# iom480ae register map
Registers are 32-bit, access not given, no defined reset value unless marked. A register's access mark holds for its fields unless they carry their own. Addresses are absolute; registers are grouped by the start of their names; [hi:lo] are bit positions; 'fields as' and 'values as' point back to an identical list.

## HSUSBD
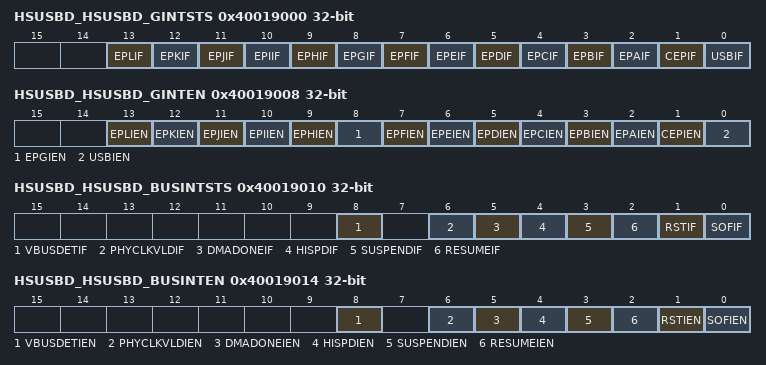
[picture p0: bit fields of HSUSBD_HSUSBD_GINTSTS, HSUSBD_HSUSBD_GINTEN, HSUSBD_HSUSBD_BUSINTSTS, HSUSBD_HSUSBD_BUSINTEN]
0x40019000 HSUSBD_HSUSBD_GINTSTS
  [13] EPLIF, [12] EPKIF, [11] EPJIF, [10] EPIIF, [9] EPHIF, [8] EPGIF, [7] EPFIF, [6] EPEIF, [5] EPDIF, [4] EPCIF, [3] EPBIF, [2] EPAIF, [1] CEPIF, [0] USBIF
0x40019008 HSUSBD_HSUSBD_GINTEN
  [13] EPLIEN, [12] EPKIEN, [11] EPJIEN, [10] EPIIEN, [9] EPHIEN, [8] EPGIEN, [7] EPFIEN, [6] EPEIEN, [5] EPDIEN, [4] EPCIEN, [3] EPBIEN, [2] EPAIEN, [1] CEPIEN, [0] USBIEN
0x40019010 HSUSBD_HSUSBD_BUSINTSTS
  [8] VBUSDETIF, [6] PHYCLKVLDIF, [5] DMADONEIF, [4] HISPDIF, [3] SUSPENDIF, [2] RESUMEIF, [1] RSTIF, [0] SOFIF
0x40019014 HSUSBD_HSUSBD_BUSINTEN
  [8] VBUSDETIEN, [6] PHYCLKVLDIEN, [5] DMADONEIEN, [4] HISPDIEN, [3] SUSPENDIEN, [2] RESUMEIEN, [1] RSTIEN, [0] SOFIEN
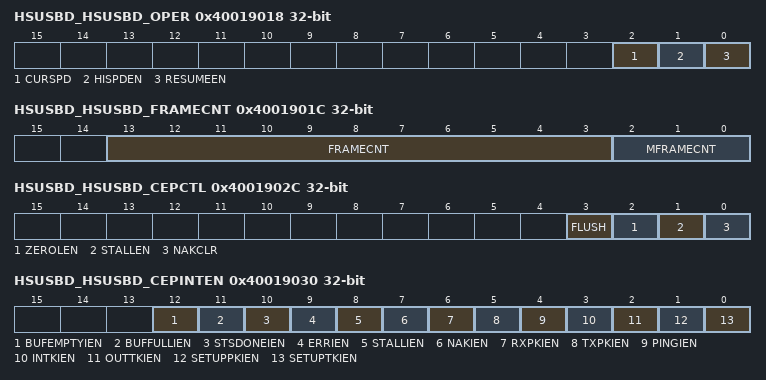
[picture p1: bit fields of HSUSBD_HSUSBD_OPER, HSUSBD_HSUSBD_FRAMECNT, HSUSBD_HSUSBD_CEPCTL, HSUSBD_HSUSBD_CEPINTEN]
0x40019018 HSUSBD_HSUSBD_OPER
  [2] CURSPD, [1] HISPDEN, [0] RESUMEEN
0x4001901C HSUSBD_HSUSBD_FRAMECNT
  [13:3] FRAMECNT, [2:0] MFRAMECNT
0x40019020 HSUSBD_HSUSBD_FADDR
  [6:0] FADDR
0x40019024 HSUSBD_HSUSBD_TEST
  [2:0] TESTMODE
0x40019028 HSUSBD_HSUSBD_CEPDAT
0x4001902C HSUSBD_HSUSBD_CEPCTL
  [3] FLUSH, [2] ZEROLEN, [1] STALLEN, [0] NAKCLR
0x40019030 HSUSBD_HSUSBD_CEPINTEN
  [12] BUFEMPTYIEN, [11] BUFFULLIEN, [10] STSDONEIEN, [9] ERRIEN, [8] STALLIEN, [7] NAKIEN, [6] RXPKIEN, [5] TXPKIEN, [4] PINGIEN, [3] INTKIEN, [2] OUTTKIEN, [1] SETUPPKIEN, [0] SETUPTKIEN
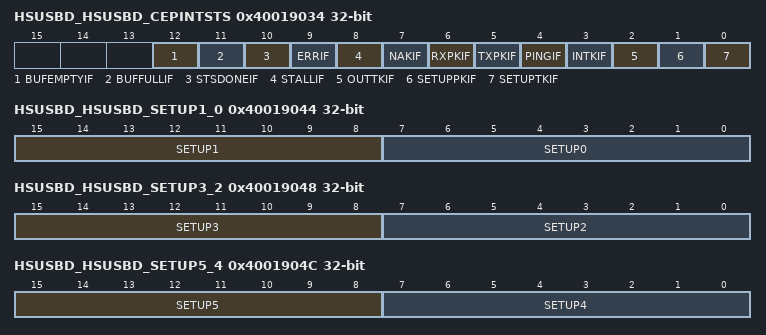
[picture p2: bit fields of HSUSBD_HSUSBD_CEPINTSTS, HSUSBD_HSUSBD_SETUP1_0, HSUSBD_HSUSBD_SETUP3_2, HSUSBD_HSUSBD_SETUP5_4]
0x40019034 HSUSBD_HSUSBD_CEPINTSTS
  [12] BUFEMPTYIF, [11] BUFFULLIF, [10] STSDONEIF, [9] ERRIF, [8] STALLIF, [7] NAKIF, [6] RXPKIF, [5] TXPKIF, [4] PINGIF, [3] INTKIF, [2] OUTTKIF, [1] SETUPPKIF, [0] SETUPTKIF
0x40019038 HSUSBD_HSUSBD_CEPTXCNT
  [7:0] TXCNT
0x4001903C HSUSBD_HSUSBD_CEPRXCNT
  [7:0] RXCNT
0x40019040 HSUSBD_HSUSBD_CEPDATCNT
  [15:0] DATCNT
0x40019044 HSUSBD_HSUSBD_SETUP1_0
  [15:8] SETUP1, [7:0] SETUP0
0x40019048 HSUSBD_HSUSBD_SETUP3_2
  [15:8] SETUP3, [7:0] SETUP2
0x4001904C HSUSBD_HSUSBD_SETUP5_4
  [15:8] SETUP5, [7:0] SETUP4
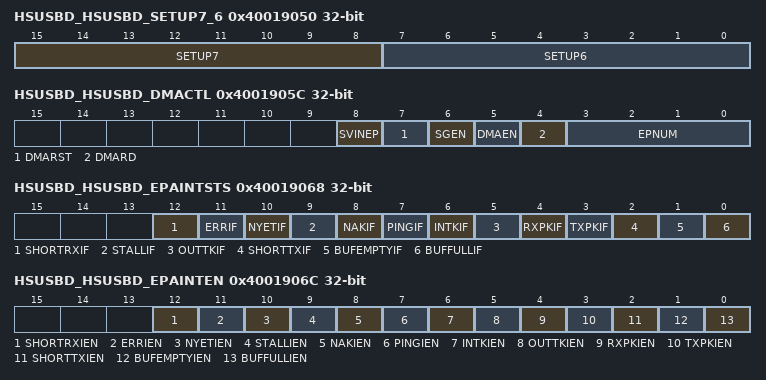
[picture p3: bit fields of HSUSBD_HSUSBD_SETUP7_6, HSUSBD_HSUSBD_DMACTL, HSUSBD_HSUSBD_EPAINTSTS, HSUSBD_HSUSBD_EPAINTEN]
0x40019050 HSUSBD_HSUSBD_SETUP7_6
  [15:8] SETUP7, [7:0] SETUP6
0x40019054 HSUSBD_HSUSBD_CEPBUFSTART
  [11:0] SADDR
0x40019058 HSUSBD_HSUSBD_CEPBUFEND
  [11:0] EADDR
0x4001905C HSUSBD_HSUSBD_DMACTL
  [8] SVINEP, [7] DMARST, [6] SGEN, [5] DMAEN, [4] DMARD, [3:0] EPNUM
0x40019060 HSUSBD_HSUSBD_DMACNT
  [19:0] DMACNT
0x40019064 HSUSBD_HSUSBD_EPADAT
0x40019068 HSUSBD_HSUSBD_EPAINTSTS
  [12] SHORTRXIF, [11] ERRIF, [10] NYETIF, [9] STALLIF, [8] NAKIF, [7] PINGIF, [6] INTKIF, [5] OUTTKIF, [4] RXPKIF, [3] TXPKIF, [2] SHORTTXIF, [1] BUFEMPTYIF, [0] BUFFULLIF
0x4001906C HSUSBD_HSUSBD_EPAINTEN
  [12] SHORTRXIEN, [11] ERRIEN, [10] NYETIEN, [9] STALLIEN, [8] NAKIEN, [7] PINGIEN, [6] INTKIEN, [5] OUTTKIEN, [4] RXPKIEN, [3] TXPKIEN, [2] SHORTTXIEN, [1] BUFEMPTYIEN, [0] BUFFULLIEN
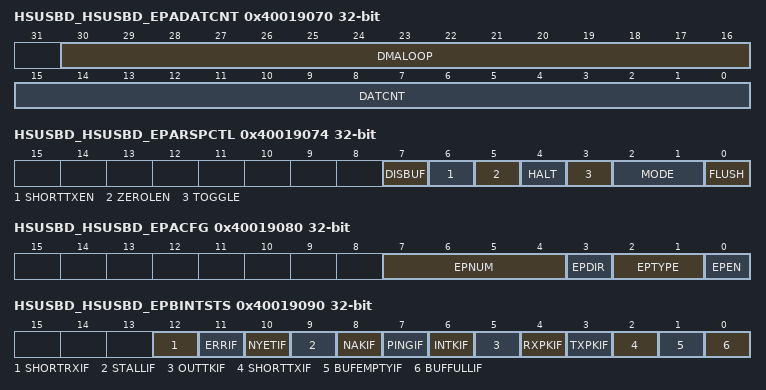
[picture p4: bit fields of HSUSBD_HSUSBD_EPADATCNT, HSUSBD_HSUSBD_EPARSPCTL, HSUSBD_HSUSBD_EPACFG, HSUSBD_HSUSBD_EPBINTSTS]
0x40019070 HSUSBD_HSUSBD_EPADATCNT
  [30:16] DMALOOP, [15:0] DATCNT
0x40019074 HSUSBD_HSUSBD_EPARSPCTL
  [7] DISBUF, [6] SHORTTXEN, [5] ZEROLEN, [4] HALT, [3] TOGGLE, [2:1] MODE, [0] FLUSH
0x40019078 HSUSBD_HSUSBD_EPAMPS
  [10:0] EPMPS
0x4001907C HSUSBD_HSUSBD_EPATXCNT
  [10:0] TXCNT
0x40019080 HSUSBD_HSUSBD_EPACFG
  [7:4] EPNUM, [3] EPDIR, [2:1] EPTYPE, [0] EPEN
0x40019084 HSUSBD_HSUSBD_EPABUFSTART
  [11:0] SADDR
0x40019088 HSUSBD_HSUSBD_EPABUFEND
  [11:0] EADDR
0x4001908C HSUSBD_HSUSBD_EPBDAT
0x40019090 HSUSBD_HSUSBD_EPBINTSTS
  fields as HSUSBD_HSUSBD_EPAINTSTS
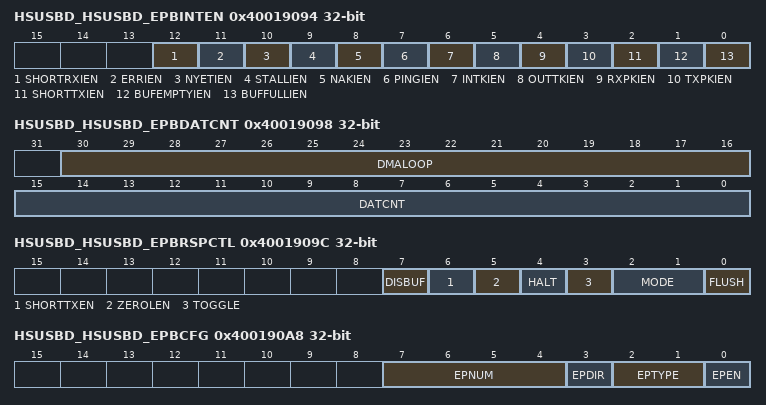
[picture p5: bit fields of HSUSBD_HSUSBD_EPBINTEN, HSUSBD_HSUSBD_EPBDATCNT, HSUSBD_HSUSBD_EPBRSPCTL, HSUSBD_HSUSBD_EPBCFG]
0x40019094 HSUSBD_HSUSBD_EPBINTEN
  fields as HSUSBD_HSUSBD_EPAINTEN
0x40019098 HSUSBD_HSUSBD_EPBDATCNT
  [30:16] DMALOOP, [15:0] DATCNT
0x4001909C HSUSBD_HSUSBD_EPBRSPCTL
  fields as HSUSBD_HSUSBD_EPARSPCTL
0x400190A0 HSUSBD_HSUSBD_EPBMPS
  [10:0] EPMPS
0x400190A4 HSUSBD_HSUSBD_EPBTXCNT
  [10:0] TXCNT
0x400190A8 HSUSBD_HSUSBD_EPBCFG
  [7:4] EPNUM, [3] EPDIR, [2:1] EPTYPE, [0] EPEN
0x400190AC HSUSBD_HSUSBD_EPBBUFSTART
  [11:0] SADDR
0x400190B0 HSUSBD_HSUSBD_EPBBUFEND
  [11:0] EADDR
0x400190B4 HSUSBD_HSUSBD_EPCDAT
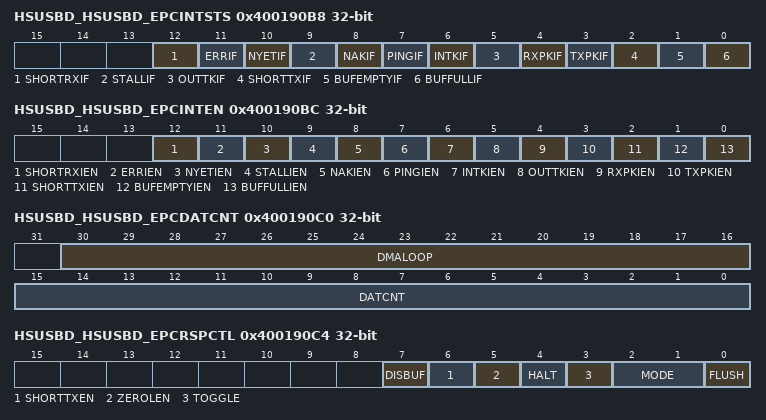
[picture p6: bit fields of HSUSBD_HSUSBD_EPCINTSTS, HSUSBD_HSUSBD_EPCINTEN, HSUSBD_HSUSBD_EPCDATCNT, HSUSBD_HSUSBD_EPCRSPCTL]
0x400190B8 HSUSBD_HSUSBD_EPCINTSTS
  fields as HSUSBD_HSUSBD_EPAINTSTS
0x400190BC HSUSBD_HSUSBD_EPCINTEN
  fields as HSUSBD_HSUSBD_EPAINTEN
0x400190C0 HSUSBD_HSUSBD_EPCDATCNT
  [30:16] DMALOOP, [15:0] DATCNT
0x400190C4 HSUSBD_HSUSBD_EPCRSPCTL
  fields as HSUSBD_HSUSBD_EPARSPCTL
0x400190C8 HSUSBD_HSUSBD_EPCMPS
  [10:0] EPMPS
0x400190CC HSUSBD_HSUSBD_EPCTXCNT
  [10:0] TXCNT
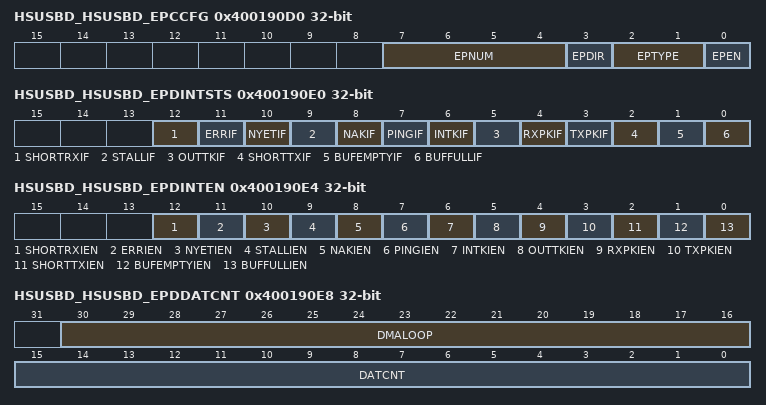
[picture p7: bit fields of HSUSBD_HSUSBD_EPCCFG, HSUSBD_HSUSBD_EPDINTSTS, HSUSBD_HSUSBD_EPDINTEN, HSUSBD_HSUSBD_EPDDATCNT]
0x400190D0 HSUSBD_HSUSBD_EPCCFG
  [7:4] EPNUM, [3] EPDIR, [2:1] EPTYPE, [0] EPEN
0x400190D4 HSUSBD_HSUSBD_EPCBUFSTART
  [11:0] SADDR
0x400190D8 HSUSBD_HSUSBD_EPCBUFEND
  [11:0] EADDR
0x400190DC HSUSBD_HSUSBD_EPDDAT
0x400190E0 HSUSBD_HSUSBD_EPDINTSTS
  fields as HSUSBD_HSUSBD_EPAINTSTS
0x400190E4 HSUSBD_HSUSBD_EPDINTEN
  fields as HSUSBD_HSUSBD_EPAINTEN
0x400190E8 HSUSBD_HSUSBD_EPDDATCNT
  [30:16] DMALOOP, [15:0] DATCNT
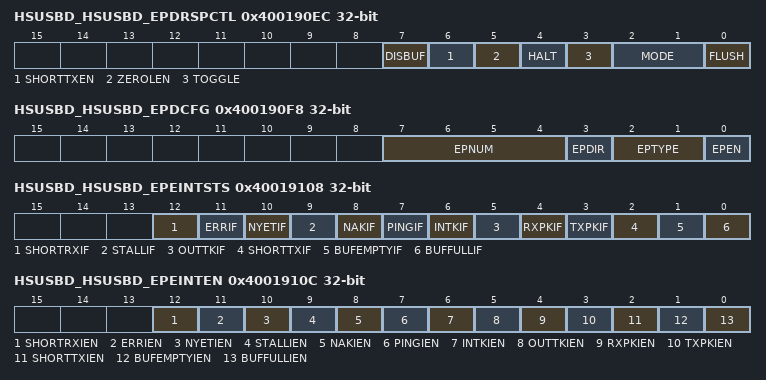
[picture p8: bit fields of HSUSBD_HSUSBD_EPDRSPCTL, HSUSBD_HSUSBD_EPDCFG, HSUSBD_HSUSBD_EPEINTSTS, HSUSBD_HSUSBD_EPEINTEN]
0x400190EC HSUSBD_HSUSBD_EPDRSPCTL
  fields as HSUSBD_HSUSBD_EPARSPCTL
0x400190F0 HSUSBD_HSUSBD_EPDMPS
  [10:0] EPMPS
0x400190F4 HSUSBD_HSUSBD_EPDTXCNT
  [10:0] TXCNT
0x400190F8 HSUSBD_HSUSBD_EPDCFG
  [7:4] EPNUM, [3] EPDIR, [2:1] EPTYPE, [0] EPEN
0x400190FC HSUSBD_HSUSBD_EPDBUFSTART
  [11:0] SADDR
0x40019100 HSUSBD_HSUSBD_EPDBUFEND
  [11:0] EADDR
0x40019104 HSUSBD_HSUSBD_EPEDAT
0x40019108 HSUSBD_HSUSBD_EPEINTSTS
  fields as HSUSBD_HSUSBD_EPAINTSTS
0x4001910C HSUSBD_HSUSBD_EPEINTEN
  fields as HSUSBD_HSUSBD_EPAINTEN
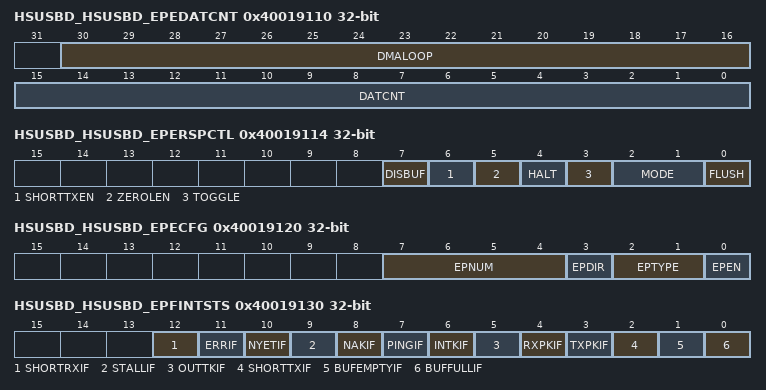
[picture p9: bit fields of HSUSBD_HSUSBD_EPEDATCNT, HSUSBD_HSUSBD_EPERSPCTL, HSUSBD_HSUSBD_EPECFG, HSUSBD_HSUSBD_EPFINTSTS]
0x40019110 HSUSBD_HSUSBD_EPEDATCNT
  [30:16] DMALOOP, [15:0] DATCNT
0x40019114 HSUSBD_HSUSBD_EPERSPCTL
  fields as HSUSBD_HSUSBD_EPARSPCTL
0x40019118 HSUSBD_HSUSBD_EPEMPS
  [10:0] EPMPS
0x4001911C HSUSBD_HSUSBD_EPETXCNT
  [10:0] TXCNT
0x40019120 HSUSBD_HSUSBD_EPECFG
  [7:4] EPNUM, [3] EPDIR, [2:1] EPTYPE, [0] EPEN
0x40019124 HSUSBD_HSUSBD_EPEBUFSTART
  [11:0] SADDR
0x40019128 HSUSBD_HSUSBD_EPEBUFEND
  [11:0] EADDR
0x4001912C HSUSBD_HSUSBD_EPFDAT
0x40019130 HSUSBD_HSUSBD_EPFINTSTS
  fields as HSUSBD_HSUSBD_EPAINTSTS
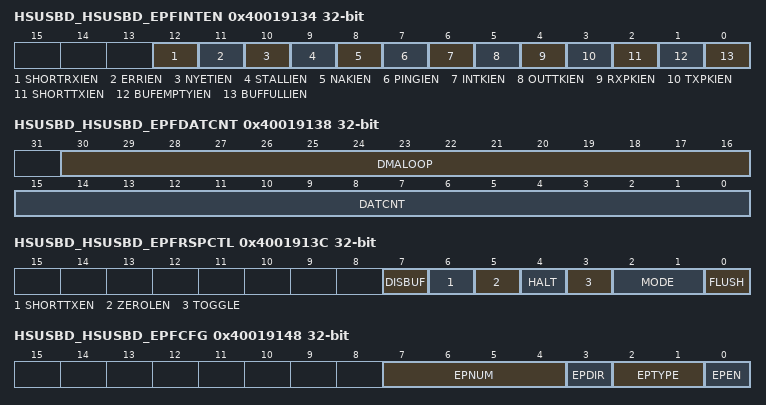
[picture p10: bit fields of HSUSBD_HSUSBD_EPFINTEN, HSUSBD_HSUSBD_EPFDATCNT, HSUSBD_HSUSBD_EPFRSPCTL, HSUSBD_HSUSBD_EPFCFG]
0x40019134 HSUSBD_HSUSBD_EPFINTEN
  fields as HSUSBD_HSUSBD_EPAINTEN
0x40019138 HSUSBD_HSUSBD_EPFDATCNT
  [30:16] DMALOOP, [15:0] DATCNT
0x4001913C HSUSBD_HSUSBD_EPFRSPCTL
  fields as HSUSBD_HSUSBD_EPARSPCTL
0x40019140 HSUSBD_HSUSBD_EPFMPS
  [10:0] EPMPS
0x40019144 HSUSBD_HSUSBD_EPFTXCNT
  [10:0] TXCNT
0x40019148 HSUSBD_HSUSBD_EPFCFG
  [7:4] EPNUM, [3] EPDIR, [2:1] EPTYPE, [0] EPEN
0x4001914C HSUSBD_HSUSBD_EPFBUFSTART
  [11:0] SADDR
0x40019150 HSUSBD_HSUSBD_EPFBUFEND
  [11:0] EADDR
0x40019154 HSUSBD_HSUSBD_EPGDAT
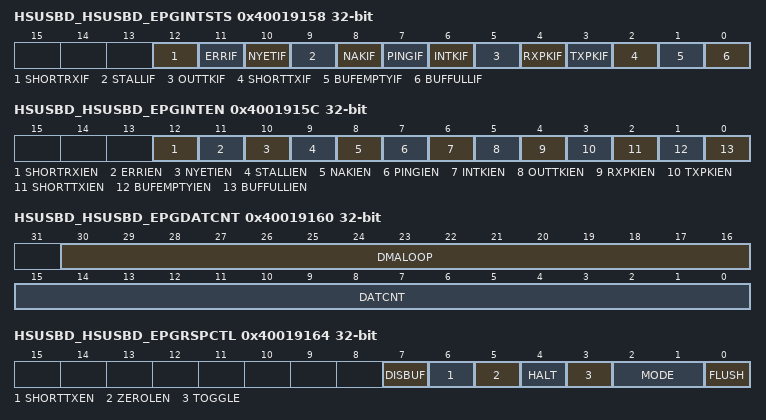
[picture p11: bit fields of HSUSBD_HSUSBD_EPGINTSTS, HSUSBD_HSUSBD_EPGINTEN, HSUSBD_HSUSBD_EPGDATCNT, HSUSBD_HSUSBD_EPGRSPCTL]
0x40019158 HSUSBD_HSUSBD_EPGINTSTS
  fields as HSUSBD_HSUSBD_EPAINTSTS
0x4001915C HSUSBD_HSUSBD_EPGINTEN
  fields as HSUSBD_HSUSBD_EPAINTEN
0x40019160 HSUSBD_HSUSBD_EPGDATCNT
  [30:16] DMALOOP, [15:0] DATCNT
0x40019164 HSUSBD_HSUSBD_EPGRSPCTL
  fields as HSUSBD_HSUSBD_EPARSPCTL
0x40019168 HSUSBD_HSUSBD_EPGMPS
  [10:0] EPMPS
0x4001916C HSUSBD_HSUSBD_EPGTXCNT
  [10:0] TXCNT
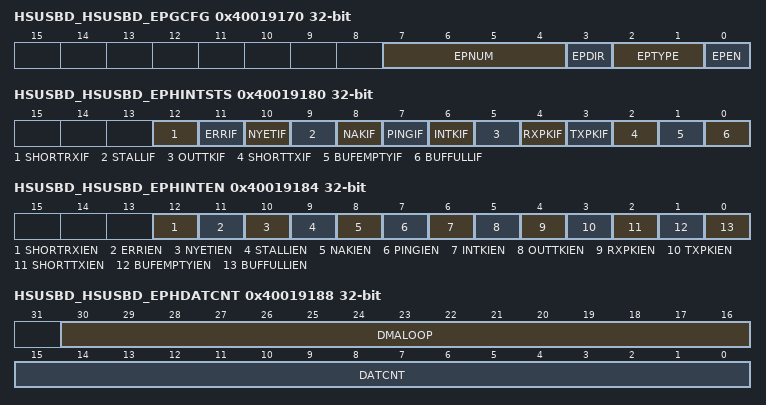
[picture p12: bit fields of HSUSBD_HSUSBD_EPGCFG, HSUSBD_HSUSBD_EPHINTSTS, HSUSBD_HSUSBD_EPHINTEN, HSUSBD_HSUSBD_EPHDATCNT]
0x40019170 HSUSBD_HSUSBD_EPGCFG
  [7:4] EPNUM, [3] EPDIR, [2:1] EPTYPE, [0] EPEN
0x40019174 HSUSBD_HSUSBD_EPGBUFSTART
  [11:0] SADDR
0x40019178 HSUSBD_HSUSBD_EPGBUFEND
  [11:0] EADDR
0x4001917C HSUSBD_HSUSBD_EPHDAT
0x40019180 HSUSBD_HSUSBD_EPHINTSTS
  fields as HSUSBD_HSUSBD_EPAINTSTS
0x40019184 HSUSBD_HSUSBD_EPHINTEN
  fields as HSUSBD_HSUSBD_EPAINTEN
0x40019188 HSUSBD_HSUSBD_EPHDATCNT
  [30:16] DMALOOP, [15:0] DATCNT
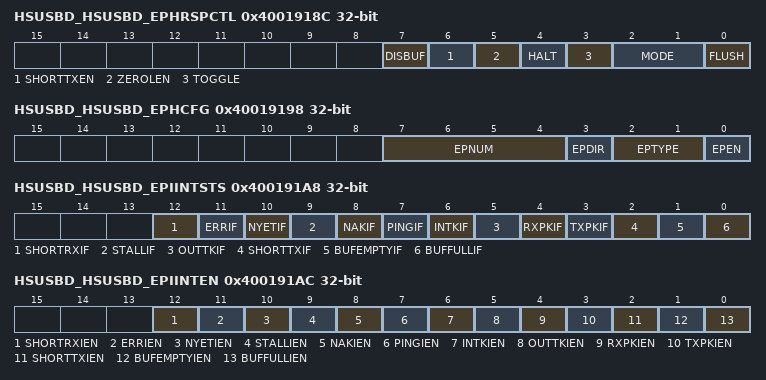
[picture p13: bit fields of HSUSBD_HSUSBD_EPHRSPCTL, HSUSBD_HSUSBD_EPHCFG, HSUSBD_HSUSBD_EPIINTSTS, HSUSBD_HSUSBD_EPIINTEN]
0x4001918C HSUSBD_HSUSBD_EPHRSPCTL
  fields as HSUSBD_HSUSBD_EPARSPCTL
0x40019190 HSUSBD_HSUSBD_EPHMPS
  [10:0] EPMPS
0x40019194 HSUSBD_HSUSBD_EPHTXCNT
  [10:0] TXCNT
0x40019198 HSUSBD_HSUSBD_EPHCFG
  [7:4] EPNUM, [3] EPDIR, [2:1] EPTYPE, [0] EPEN
0x4001919C HSUSBD_HSUSBD_EPHBUFSTART
  [11:0] SADDR
0x400191A0 HSUSBD_HSUSBD_EPHBUFEND
  [11:0] EADDR
0x400191A4 HSUSBD_HSUSBD_EPIDAT
0x400191A8 HSUSBD_HSUSBD_EPIINTSTS
  fields as HSUSBD_HSUSBD_EPAINTSTS
0x400191AC HSUSBD_HSUSBD_EPIINTEN
  fields as HSUSBD_HSUSBD_EPAINTEN
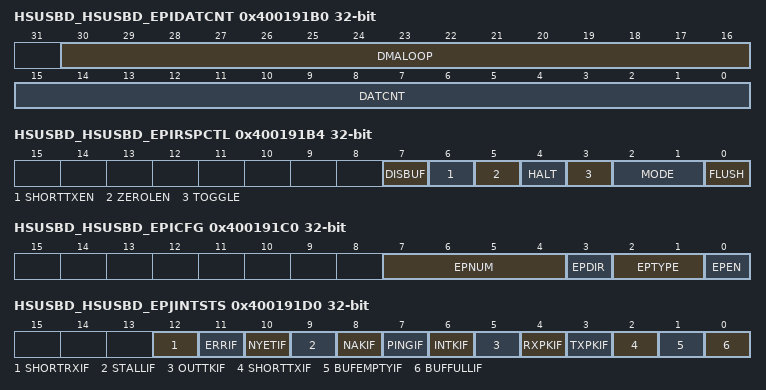
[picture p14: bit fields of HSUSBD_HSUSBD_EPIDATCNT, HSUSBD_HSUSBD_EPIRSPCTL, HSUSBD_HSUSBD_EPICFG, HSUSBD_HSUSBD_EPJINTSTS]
0x400191B0 HSUSBD_HSUSBD_EPIDATCNT
  [30:16] DMALOOP, [15:0] DATCNT
0x400191B4 HSUSBD_HSUSBD_EPIRSPCTL
  fields as HSUSBD_HSUSBD_EPARSPCTL
0x400191B8 HSUSBD_HSUSBD_EPIMPS
  [10:0] EPMPS
0x400191BC HSUSBD_HSUSBD_EPITXCNT
  [10:0] TXCNT
0x400191C0 HSUSBD_HSUSBD_EPICFG
  [7:4] EPNUM, [3] EPDIR, [2:1] EPTYPE, [0] EPEN
0x400191C4 HSUSBD_HSUSBD_EPIBUFSTART
  [11:0] SADDR
0x400191C8 HSUSBD_HSUSBD_EPIBUFEND
  [11:0] EADDR
0x400191CC HSUSBD_HSUSBD_EPJDAT
0x400191D0 HSUSBD_HSUSBD_EPJINTSTS
  fields as HSUSBD_HSUSBD_EPAINTSTS
0x400191D4 HSUSBD_HSUSBD_EPJINTEN
  fields as HSUSBD_HSUSBD_EPAINTEN
0x400191D8 HSUSBD_HSUSBD_EPJDATCNT
  [30:16] DMALOOP, [15:0] DATCNT
0x400191DC HSUSBD_HSUSBD_EPJRSPCTL
  fields as HSUSBD_HSUSBD_EPARSPCTL
0x400191E0 HSUSBD_HSUSBD_EPJMPS
  [10:0] EPMPS
0x400191E4 HSUSBD_HSUSBD_EPJTXCNT
  [10:0] TXCNT
0x400191E8 HSUSBD_HSUSBD_EPJCFG
  [7:4] EPNUM, [3] EPDIR, [2:1] EPTYPE, [0] EPEN
0x400191EC HSUSBD_HSUSBD_EPJBUFSTART
  [11:0] SADDR
0x400191F0 HSUSBD_HSUSBD_EPJBUFEND
  [11:0] EADDR
0x400191F4 HSUSBD_HSUSBD_EPKDAT
0x400191F8 HSUSBD_HSUSBD_EPKINTSTS
  fields as HSUSBD_HSUSBD_EPAINTSTS
0x400191FC HSUSBD_HSUSBD_EPKINTEN
  fields as HSUSBD_HSUSBD_EPAINTEN
0x40019200 HSUSBD_HSUSBD_EPKDATCNT
  [30:16] DMALOOP, [15:0] DATCNT
0x40019204 HSUSBD_HSUSBD_EPKRSPCTL
  fields as HSUSBD_HSUSBD_EPARSPCTL
0x40019208 HSUSBD_HSUSBD_EPKMPS
  [10:0] EPMPS
0x4001920C HSUSBD_HSUSBD_EPKTXCNT
  [10:0] TXCNT
0x40019210 HSUSBD_HSUSBD_EPKCFG
  [7:4] EPNUM, [3] EPDIR, [2:1] EPTYPE, [0] EPEN
0x40019214 HSUSBD_HSUSBD_EPKBUFSTART
  [11:0] SADDR
0x40019218 HSUSBD_HSUSBD_EPKBUFEND
  [11:0] EADDR
0x4001921C HSUSBD_HSUSBD_EPLDAT
0x40019220 HSUSBD_HSUSBD_EPLINTSTS
  fields as HSUSBD_HSUSBD_EPAINTSTS
0x40019224 HSUSBD_HSUSBD_EPLINTEN
  fields as HSUSBD_HSUSBD_EPAINTEN
0x40019228 HSUSBD_HSUSBD_EPLDATCNT
  [30:16] DMALOOP, [15:0] DATCNT
0x4001922C HSUSBD_HSUSBD_EPLRSPCTL
  fields as HSUSBD_HSUSBD_EPARSPCTL
0x40019230 HSUSBD_HSUSBD_EPLMPS
  [10:0] EPMPS
0x40019234 HSUSBD_HSUSBD_EPLTXCNT
  [10:0] TXCNT
0x40019238 HSUSBD_HSUSBD_EPLCFG
  [7:4] EPNUM, [3] EPDIR, [2:1] EPTYPE, [0] EPEN
0x4001923C HSUSBD_HSUSBD_EPLBUFSTART
  [11:0] SADDR
0x40019240 HSUSBD_HSUSBD_EPLBUFEND
  [11:0] EADDR
0x40019700 HSUSBD_HSUSBD_DMAADDR
0x40019704 HSUSBD_HSUSBD_PHYCTL
  [31] VBUSDET, [24] WKEN, [9] PHYEN, [8] DPPUEN
